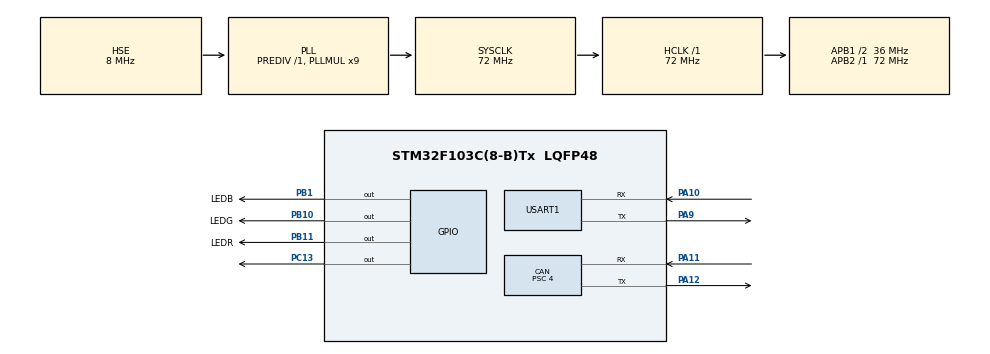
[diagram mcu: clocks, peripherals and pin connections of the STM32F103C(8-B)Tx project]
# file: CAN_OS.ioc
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CAN.BS1=CAN_BS1_14TQ
CAN.BS2=CAN_BS2_3TQ
CAN.CalculateBaudRate=500000
CAN.CalculateTimeBit=2000
CAN.CalculateTimeQuantum=111.11111111111111
CAN.Prescaler=4
CAN.SJW=CAN_SJW_2TQ
Dma.MEMTOMEM.0.Direction=DMA_MEMORY_TO_MEMORY
Dma.MEMTOMEM.0.Instance=DMA1_Channel1
Dma.MEMTOMEM.0.MemDataAlignment=DMA_MDATAALIGN_BYTE
Dma.MEMTOMEM.0.MemInc=DMA_MINC_ENABLE
Dma.MEMTOMEM.0.Mode=DMA_NORMAL
Dma.MEMTOMEM.0.PeriphDataAlignment=DMA_PDATAALIGN_BYTE
Dma.MEMTOMEM.0.PeriphInc=DMA_PINC_ENABLE
Dma.MEMTOMEM.0.Priority=DMA_PRIORITY_LOW
Dma.Request0=MEMTOMEM
FREERTOS.Tasks01=mMainTask,24,256,MainTask,Default,NULL,Dynamic,NULL,NULL;mCanRecv,8,256,CanRecv,Default,NULL,Dynamic,NULL,NULL;myDataProcessin,40,128,DataProcessing,Default,NULL,Dynamic,NULL,NULL
Mcu.Family=STM32F1
Mcu.Name=STM32F103C(8-B)Tx
Mcu.Package=LQFP48
NVIC.CAN1_RX1_IRQn=true\:5\:0\:false\:false\:true\:true\:true\:true\:true
NVIC.CAN1_SCE_IRQn=true\:5\:0\:false\:false\:true\:true\:true\:true\:true
NVIC.PriorityGroup=NVIC_PRIORITYGROUP_4
NVIC.TIM3_IRQn=true\:5\:0\:false\:false\:true\:true\:true\:true\:true
NVIC.TIM4_IRQn=true\:15\:0\:false\:false\:true\:false\:false\:true\:true
NVIC.TimeBase=TIM4_IRQn
NVIC.TimeBaseIP=TIM4
NVIC.USB_HP_CAN1_TX_IRQn=true\:5\:0\:false\:false\:true\:true\:true\:true\:true
NVIC.USB_LP_CAN1_RX0_IRQn=true\:5\:0\:false\:false\:true\:true\:true\:true\:true
PA10.Mode=Asynchronous
PA10.Signal=USART1_RX
PA11.Mode=CAN_Activate
PA11.Signal=CAN_RX
PA12.Mode=CAN_Activate
PA12.Signal=CAN_TX
PA13.Mode=Serial_Wire
PA13.Signal=SYS_JTMS-SWDIO
PA14.Mode=Serial_Wire
PA14.Signal=SYS_JTCK-SWCLK
PA9.Mode=Asynchronous
PA9.Signal=USART1_TX
PB1.GPIO_Label=LEDB
PB1.Signal=GPIO_Output
PB10.GPIO_Label=LEDG
PB10.Signal=GPIO_Output
PB11.GPIO_Label=LEDR
PB11.Signal=GPIO_Output
PC13-TAMPER-RTC.Signal=GPIO_Output
PD0-OSC_IN.Mode=HSE-External-Oscillator
PD0-OSC_IN.Signal=RCC_OSC_IN
PD1-OSC_OUT.Mode=HSE-External-Oscillator
PD1-OSC_OUT.Signal=RCC_OSC_OUT
ProjectManager.HeapSize=0x200
ProjectManager.StackSize=0x400
ProjectManager.TargetToolchain=STM32CubeIDE
RCC.AHBFreq_Value=72000000
RCC.APB1CLKDivider=RCC_HCLK_DIV2
RCC.APB1Freq_Value=36000000
RCC.APB1TimFreq_Value=72000000
RCC.APB2Freq_Value=72000000
RCC.APB2TimFreq_Value=72000000
RCC.HCLKFreq_Value=72000000
RCC.PLLMUL=RCC_PLL_MUL9
RCC.PLLSourceVirtual=RCC_PLLSOURCE_HSE
RCC.SYSCLKFreq_VALUE=72000000
RCC.SYSCLKSource=RCC_SYSCLKSOURCE_PLLCLK
RCC.USBFreq_Value=72000000
TIM3.Period=209
TIM3.Prescaler=71
USART1.VirtualMode=VM_ASYNC
VP_FREERTOS_VS_CMSIS_V2.Mode=CMSIS_V2
VP_SYS_VS_tim4.Mode=TIM4
VP_TIM3_VS_ClockSourceINT.Mode=Internal
board=custom

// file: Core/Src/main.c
/* USER CODE BEGIN Header */
/**
  ******************************************************************************
  * @file           : main.c
  * @brief          : Main program body
  ******************************************************************************
  * @attention
  *
  * Copyright (c) 2023 STMicroelectronics.
  * All rights reserved.
  *
  * This software is licensed under terms that can be found in the LICENSE file
  * in the root directory of this software component.
  * If no LICENSE file comes with this software, it is provided AS-IS.
  *
  ******************************************************************************
  */
/* USER CODE END Header */
#include "main.h"
#include "cmsis_os.h"
#include "can.h"
#include "dma.h"
#include "tim.h"
#include "usart.h"
#include "gpio.h"

void SystemClock_Config(void);
void MX_FREERTOS_Init(void);

int main(void)
{

  /* MCU Configuration--------------------------------------------------------*/

  /* Reset of all peripherals, Initializes the Flash interface and the Systick. */
  HAL_Init();

  /* Configure the system clock */
  SystemClock_Config();

  /* Initialize all configured peripherals */
  MX_GPIO_Init();
  MX_DMA_Init();
  MX_CAN_Init();
  MX_TIM3_Init();
  MX_USART1_UART_Init();
  /* USER CODE BEGIN 2 */
  CAN_Config_filtering(CAN_FILTER_FIFO0);
 // CAN_Config_filtering(CAN_FILTER_FIFO1);
      if(HAL_CAN_Start(&hcan)!=HAL_OK)
          {
           Error_Handler();
          }
  /* USER CODE END 2 */

  /* Init scheduler */
  osKernelInitialize();  /* Call init function for freertos objects (in freertos.c) */
  MX_FREERTOS_Init();

  /* Start scheduler */
  osKernelStart();

  /* We should never get here as control is now taken by the scheduler */
  /* Infinite loop */
  while (1)
  {

  }
}

void SystemClock_Config(void)
{
  RCC_OscInitTypeDef RCC_OscInitStruct = {0};
  RCC_ClkInitTypeDef RCC_ClkInitStruct = {0};

  /** Initializes the RCC Oscillators according to the specified parameters
  * in the RCC_OscInitTypeDef structure.
  */
  RCC_OscInitStruct.OscillatorType = RCC_OSCILLATORTYPE_HSE;
  RCC_OscInitStruct.HSEState = RCC_HSE_ON;
  RCC_OscInitStruct.HSEPredivValue = RCC_HSE_PREDIV_DIV1;
  RCC_OscInitStruct.HSIState = RCC_HSI_ON;
  RCC_OscInitStruct.PLL.PLLState = RCC_PLL_ON;
  RCC_OscInitStruct.PLL.PLLSource = RCC_PLLSOURCE_HSE;
  RCC_OscInitStruct.PLL.PLLMUL = RCC_PLL_MUL9;
  if (HAL_RCC_OscConfig(&RCC_OscInitStruct) != HAL_OK)
  {
    Error_Handler();
  }

  /** Initializes the CPU, AHB and APB buses clocks
  */
  RCC_ClkInitStruct.ClockType = RCC_CLOCKTYPE_HCLK|RCC_CLOCKTYPE_SYSCLK
                              |RCC_CLOCKTYPE_PCLK1|RCC_CLOCKTYPE_PCLK2;
  RCC_ClkInitStruct.SYSCLKSource = RCC_SYSCLKSOURCE_PLLCLK;
  RCC_ClkInitStruct.AHBCLKDivider = RCC_SYSCLK_DIV1;
  RCC_ClkInitStruct.APB1CLKDivider = RCC_HCLK_DIV2;
  RCC_ClkInitStruct.APB2CLKDivider = RCC_HCLK_DIV1;

  if (HAL_RCC_ClockConfig(&RCC_ClkInitStruct, FLASH_LATENCY_2) != HAL_OK)
  {
    Error_Handler();
  }
}

void HAL_TIM_PeriodElapsedCallback(TIM_HandleTypeDef *htim)
{
  if (htim->Instance == TIM4) {
    HAL_IncTick();
  }
}

void Error_Handler(void)
{
  __disable_irq();
  while (1)
  {
  }
}
